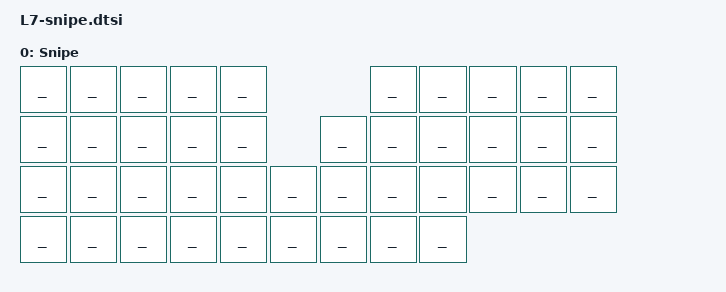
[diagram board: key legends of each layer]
/**
 * Held with the Z key on the Mouse layer: the trackball runs at the slowest speed level
 * (see boards/shields/mona2/trackball_input.dtsi). Every key falls through to the Mouse layer.
 */

/ {
  keymap {
    compatible = "zmk,keymap";

	snipe_layer {
		label = "Snipe";
		bindings = <
	________        ________        ________        ________        ________                                            ________        ________        ________        ________        ________
	________        ________        ________        ________        ________                            ________        ________        ________        ________        ________        ________
	________        ________        ________        ________        ________        ________            ________        ________        ________        ________        ________        ________
	________        ________        ________        ________        ________        ________            ________        ________        ________
		>;
	};
  };
};
